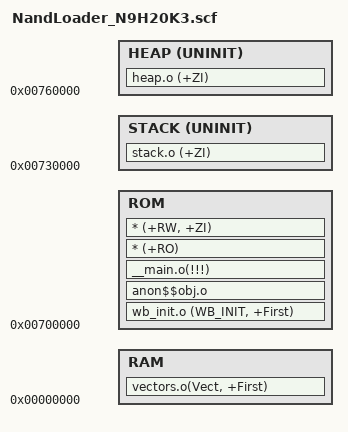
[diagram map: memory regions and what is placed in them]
;/**************************************************************************//**
; * @file     NandLoader_N9H20K3.scf
; * @brief    NandLoader scf file for N9H20K3 series.
; *
; * SPDX-License-Identifier: Apache-2.0
; * @copyright (C) 2020 Nuvoton Technology Corp. All rights reserved.
; *****************************************************************************/

ROM_LOAD 0x700000
{
    ROM +0
    {
        wb_init.o (WB_INIT, +First)
        anon$$obj.o
        __main.o(!!!)
        * (+RO)
        * (+RW, +ZI) 
        
    }
    
    RAM 0x0
    {
        vectors.o(Vect, +First)  
    }
      
    
    HEAP 0x760000 UNINIT    
    {
        heap.o (+ZI)
    }

	STACK 0x730000 UNINIT	
	{
		stack.o (+ZI)
	}    
}
